# EFR32FG22C121F512GM32 register map
Vendor: Silicon Labs; Series: EFR32; File version: C
Registers are 32-bit, read-write, reset 0x0 unless marked. A register's access mark holds for its fields unless they carry their own. Offsets are from the block's base; [hi:lo] are bit positions; {n}, {i} and the like mark numbered series; 'fields as' and 'values as' point back to an identical list.

## RAC_S — RAC_S Registers
Base 0xA8020000
Same registers: RAC_NS 0xB8020000
0x00 IPVERSION ro reset 0x1
0x04 EN
  [0] EN — Enable peripheral clock to this module
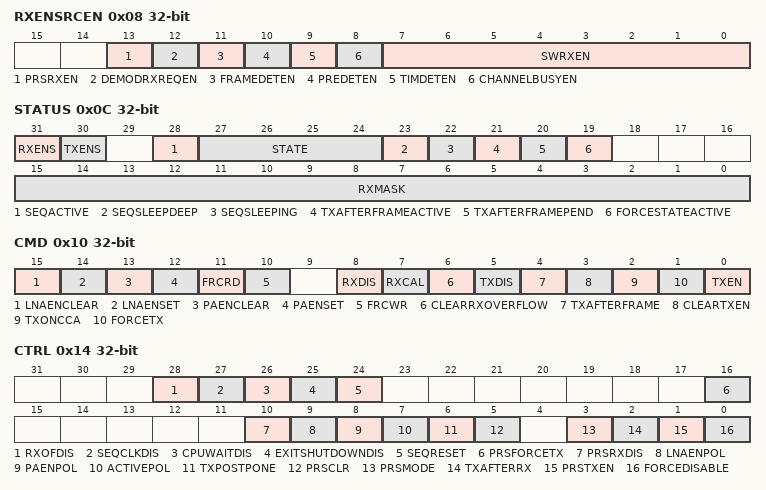
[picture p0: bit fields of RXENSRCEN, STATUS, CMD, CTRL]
0x08 RXENSRCEN
  [13] PRSRXEN — PRS RX Enable
  [12] DEMODRXREQEN — DEMOD RX Request Enable
  [11] FRAMEDETEN — Frame Detected Enable
  [10] PREDETEN — Preamble Detected Enable
  [9] TIMDETEN — Timing Detected Enable
  [8] CHANNELBUSYEN — Channel Busy Enable
  [7:0] SWRXEN — SW RX Enable
0x0C STATUS ro
  [31] RXENS — RXEN Status
    0=RXEN is not set; 1=RXEN is set
  [30] TXENS — TXEN Status
    0=TXEN is not set; 1=TXEN is set
  [28] SEQACTIVE
  [27:24] STATE — Radio State
    0=OFF (Radio is off); 1=RXWARM (Radio is enabling receiver); 2=RXSEARCH (Radio is listening for incoming frames); 3=RXFRAME (Radio is receiving a frame); 4=RXPD (Radio is powering down receiver and going to OFF state); 5=RX2RX (Radio remains in receive mode after frame reception is completed); 6=RXOVERFLOW (Received data was lost due to full receive buffer); 7=RX2TX (Radio is disabling receiver and enabling transmitter); 8=TXWARM (Radio is enabling transmitter); 9=TX (Radio is transmitting data); 10=TXPD (Radio is powering down transmitter and going to OFF state); 11=TX2RX (Radio is disabling transmitter and enabling reception); 12=TX2TX (Radio is preparing for a transmission after the previous transmission was ended); 13=SHUTDOWN (Radio is powering down receiver and going to OFF state); 14=POR (Radio power-on-reset state)
  [23] SEQSLEEPDEEP — SEQ in deep sleep
  [22] SEQSLEEPING — SEQ in sleeping
  [21] TXAFTERFRAMEACTIVE
    0=The currently ongoing TX was not initiated by a TXAFTERFRAME command; 1=The currently ongoing TX was initiated by a TXAFTERFRAME command
  [20] TXAFTERFRAMEPEND — TX After Frame Pending
    0=A transmit after frame operation is currently not pending; 1=A transmit after frame operation is currently pending
  [19] FORCESTATEACTIVE — FSM state force active
    0=No special state transition is currently in progress; 1=A forced state transition is currently in progress
  [15:0] RXMASK — Receive Enable Mask
0x10 CMD wo
  [15] LNAENCLEAR
  [14] LNAENSET
  [13] PAENCLEAR
  [12] PAENSET
  [11] FRCRD — FRC read cmd
  [10] FRCWR — FRC write cmd
  [8] RXDIS — RX Disable
  [7] RXCAL — Start an RX Calibration
  [6] CLEARRXOVERFLOW
  [5] TXDIS — TX Disable
  [4] TXAFTERFRAME
  [3] CLEARTXEN — Clear TX Enable
  [2] TXONCCA — Transmit On CCA
  [1] FORCETX — Force TX Command
  [0] TXEN — Transmitter Enable
0x14 CTRL
  [28] RXOFDIS — Switch to RXOVERFLOW Disable
  [27] SEQCLKDIS — SEQ Clk Disable
  [26] CPUWAITDIS — SEQ CPU Wait Disable
  [25] EXITSHUTDOWNDIS — Exit SHUTDOWN state Disable
  [24] SEQRESET wo
  [16] PRSFORCETX — PRS Force RX
    0=PRS will not force TX; 1=The channel selected by PRSFORCETXSEL will generate a force TX pulse
  [10] PRSRXDIS — PRS RX Disable
    0=PRS will not disable RX; 1=The channel selected by PRSRXDISSEL will generate a disable RX pulse
  [9] LNAENPOL — LNAEN signal polarity
    0=Active low; 1=Active high
  [8] PAENPOL — PAEN signal polarity
    0=Active low; 1=Active high
  [7] ACTIVEPOL — ACTIVE signal polarity
    0=Active low; 1=Active high
  [6] TXPOSTPONE
    0=In the TX state transmit data is output; 1=In the TX state an unmodulated carrier is output until this bit is cleared
  [5] PRSCLR — PRS RXEN Clear
    0=RXSEARCH (The PRS RXEN signal is cleared when the RSM state enters RXSEARCH); 1=PRSCH (The Selected PRS channel in PRSCLRSEL is used as a disable pulse)
  [3] PRSMODE — PRS RXEN Mode
    0=DIRECT (The PRS signal is used directly); 1=PULSE (The PRS signal is used as an RX enable pulse)
  [2] TXAFTERRX
    0=TX will not be started automatically; 1=A transition to TX is automatically started when a received frame is accepted by the FRC
  [1] PRSTXEN — PRS TX Enable
  [0] FORCEDISABLE — Force Radio Disable
0x18 FORCESTATE
  [3:0] FORCESTATE — Force RAC state transition
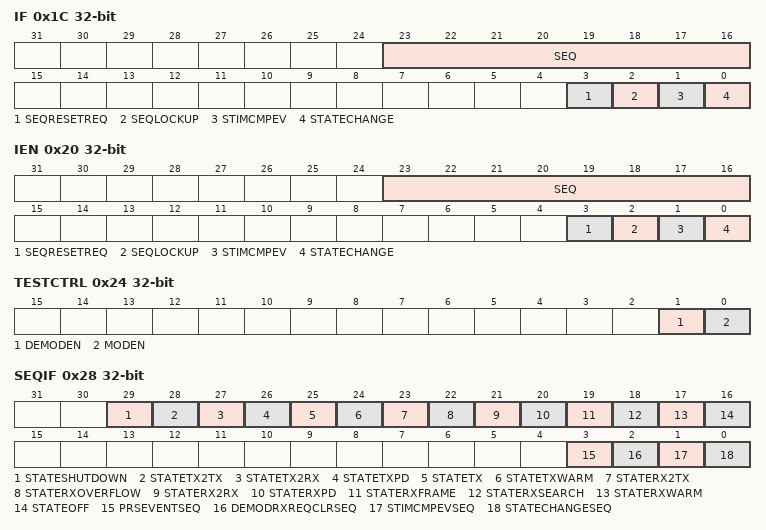
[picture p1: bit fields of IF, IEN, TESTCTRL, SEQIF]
0x1C IF
  [23:16] SEQ — Sequencer Interrupt Flags
  [3] SEQRESETREQ — SEQ reset request
  [2] SEQLOCKUP — SEQ locked up
  [1] STIMCMPEV — STIMER Compare Event
  [0] STATECHANGE — Radio State Change
0x20 IEN
  [23:16] SEQ — Sequencer Flags Interrupt Enable
  [3] SEQRESETREQ — SEQ reset request Interrupt Enable
  [2] SEQLOCKUP — SEQ locked up Interrupt Enable
  [1] STIMCMPEV — STIMER Compare Event Interrupt Enable
  [0] STATECHANGE — Radio State Change Interrupt Enable
0x24 TESTCTRL
  [1] DEMODEN — Demodulator enable
  [0] MODEN — Modulator enable
0x28 SEQIF
  [29] STATESHUTDOWN — entering STATE_SHUTDOWN
  [28] STATETX2TX — entering STATE_TX2TX
  [27] STATETX2RX — entering STATE_TX2RX
  [26] STATETXPD — entering STATE_TXPD
  [25] STATETX — entering STATE_TX
  [24] STATETXWARM — entering STATE_TXWARM
  [23] STATERX2TX — entering STATE_RX2TX
  [22] STATERXOVERFLOW — entering STATE_RXOVERFLOW
  [21] STATERX2RX — entering STATE_RX2RX
  [20] STATERXPD — entering STATE_RXPD
  [19] STATERXFRAME — entering STATE_RXFRAME
  [18] STATERXSEARCH — entering STATE_RXSEARCH
  [17] STATERXWARM — entering STATE_RXWARM
  [16] STATEOFF — entering STATE_OFF
  [3] PRSEVENTSEQ — SEQ PRS Event
  [2] DEMODRXREQCLRSEQ — Demod RX request clear
  [1] STIMCMPEVSEQ — STIMER Compare Event
  [0] STATECHANGESEQ — Radio State Change
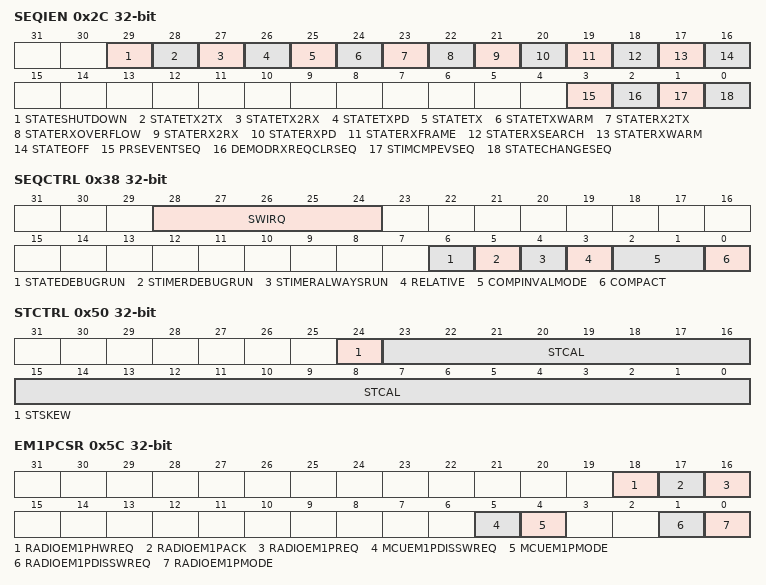
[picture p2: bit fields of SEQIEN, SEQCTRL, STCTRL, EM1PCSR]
0x2C SEQIEN
  [29] STATESHUTDOWN — STATE_SHUTDOWN Interrupt Enable
  [28] STATETX2TX — STATE_TX2TX Interrupt Enable
  [27] STATETX2RX — STATE_TX2RX Interrupt Enable
  [26] STATETXPD — STATE_TXPD Interrupt Enable
  [25] STATETX — STATE_TX Interrupt Enable
  [24] STATETXWARM — STATE_TXWARM Interrupt Enable
  [23] STATERX2TX — STATE_RX2TX Interrupt Enable
  [22] STATERXOVERFLOW — STATE_RXOVERFLOW Interrupt Enable
  [21] STATERX2RX — STATE_RX2RX Interrupt Enable
  [20] STATERXPD — STATE_RXPD Interrupt Enable
  [19] STATERXFRAME — STATE_RXFRAME Interrupt Enable
  [18] STATERXSEARCH — STATE_RXSEARC Interrupt Enable
  [17] STATERXWARM — STATE_RXWARM Interrupt Enable
  [16] STATEOFF — STATE_OFF Interrupt Enable
  [3] PRSEVENTSEQ — PRS SEQ EVENT Interrupt Enable
  [2] DEMODRXREQCLRSEQ — Demod RX req clr Interrupt Enable
  [1] STIMCMPEVSEQ — STIMER Compare Event Interrupt Enable
  [0] STATECHANGESEQ — Radio State Change Interrupt Enable
0x30 STIMER ro
  [15:0] STIMER
0x34 STIMERCOMP
  [15:0] STIMERCOMP — STIMER Compare Register
0x38 SEQCTRL
  [28:24] SWIRQ — SW spare IRQ
  [6] STATEDEBUGRUN — FSM state Debug Run
    0=FSM keeps unchanged when the Sequencer is halted; 1=FSM keeps going when the Sequencer is halted
  [5] STIMERDEBUGRUN
    0=STIMER is not running when the Sequencer is halted; 1=STIMER is running when the Sequencer is halted
  [4] STIMERALWAYSRUN
  [3] RELATIVE — STIMER Compare value relative
    0=Absolute (The compare value set for stimer is an absolute value.); 1=Relative (The compare value set for stimer is a relative value. It takes the amount of time you set to make compare event happens.)
  [2:1] COMPINVALMODE — STIMER Comp Invalid Mode
    0=NEVER (STIMERCOMP is always valid); 1=STATECHANGE (STIMERCOMP is invalidated when the RSM changes state); 2=COMPEVENT (STIMERCOMP is invalidated when an STIMER compare event occurs); 3=STATECOMP (STIMERCOMP is invalidated both when the RSM changes state and when a compare event occurs)
  [0] COMPACT — STIMER Compare Action
    0=WRAP (STIMER wraps when reaching STIMERCOMP); 1=CONTINUE (STIMER continues when reaching STIMERCOMP)
0x3C PRESC reset 0x7
  [6:0] STIMER — STIMER Prescaler
{0x40+4i} SR{i} (i=0..3)
  [31:0] SR{i} — Sequencer Storage Register {i}
0x50 STCTRL
  [24] STSKEW — Systick timer skew
  [23:0] STCAL — Systick timer freq cal
0x54 FRCTXWORD
  [7:0] WDATA — FRC write data
0x58 FRCRXWORD ro
  [7:0] RDATA — FRC read data
0x5C EM1PCSR
  [18] RADIOEM1PHWREQ ro
  [17] RADIOEM1PACK ro
  [16] RADIOEM1PREQ ro
  [5] MCUEM1PDISSWREQ
  [4] MCUEM1PMODE
    0=HWCTRL (Hardware Controls EM1P Request Signal.); 1=SWCTRL (Software Controls EM1P Request Signal)
  [1] RADIOEM1PDISSWREQ
  [0] RADIOEM1PMODE
    0=HWCTRL (Hardware Controls EM1P Request Signal); 1=SWCTRL (Software Controls EM1P Request Signal)
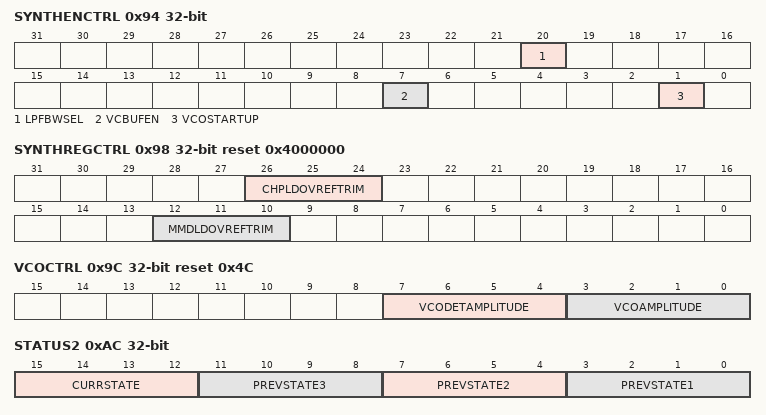
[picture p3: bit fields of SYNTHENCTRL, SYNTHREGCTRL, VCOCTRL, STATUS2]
0x94 SYNTHENCTRL
  [20] LPFBWSEL — LPF bandwidth register selection
    0=LPFBWRX (Select LPFBWRX); 1=LPFBWTX (Select LPFBWTX)
  [7] VCBUFEN — SYLPFVCBUFEN
    0=Disabled; 1=Enabled
  [1] VCOSTARTUP — SYVCOFASTSTARTUP
    0=fast_start_up_0; 1=fast_start_up_1
0x98 SYNTHREGCTRL reset 0x4000000
  [26:24] CHPLDOVREFTRIM — SYTRIMCHPREGVREF
    0=vref0p6000; 1=vref0p6125; 2=vref0p6250; 3=vref0p6375; 4=vref0p6500; 5=vref0p6625; 6=vref0p6750; 7=vref0p6875
  [12:10] MMDLDOVREFTRIM — SYTRIMMMDREGVREF
    values as CHPLDOVREFTRIM
0x9C VCOCTRL reset 0x4C
  [7:4] VCODETAMPLITUDE — SYVCOAMPLPKD
  [3:0] VCOAMPLITUDE — SYVCOAMPLOPEN
0xA4 SYNTHCTRL
  [10] MMDPOWERBALANCEDISABLE — SYMMDPOWERBALANCEENB
    0=EnablePowerbleed; 1=DisablePowerBleed
0xAC STATUS2 ro
  [all] fields
    values as STATUS.STATE
  [15:12] CURRSTATE — Current Radio State
  [11:8] PREVSTATE3 — Previous Radio State 3
  [7:4] PREVSTATE2 — Previous Radio State 2
  [3:0] PREVSTATE1 — Previous Radio State
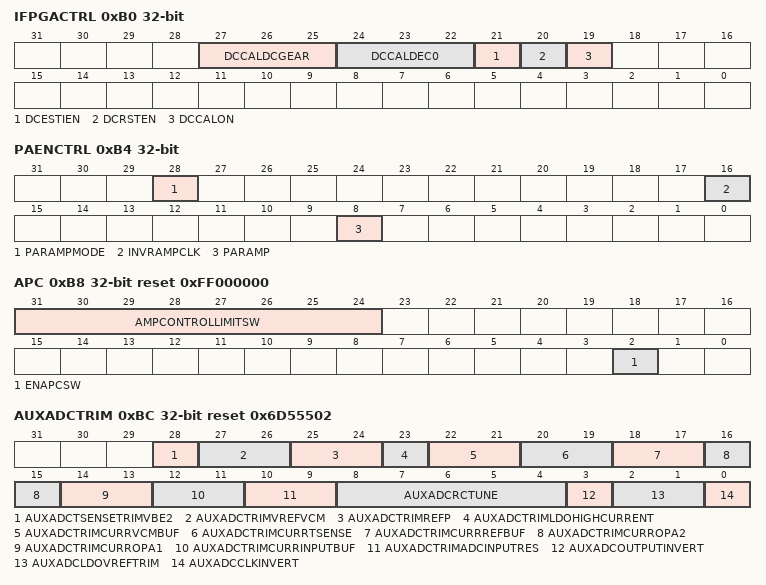
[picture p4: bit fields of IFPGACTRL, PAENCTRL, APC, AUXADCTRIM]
0xB0 IFPGACTRL
  [27:25] DCCALDCGEAR — DC COMP GEAR Value for DCCAL
  [24:22] DCCALDEC0 — DEC0 Value for DCCAL
    0=DF3 (Decimation Factor 0 = 3. Cutoff 0.050 * f<subscript>HFXO</subscript>.); 1=DF4WIDE (Decimation Factor 0 = 4. Cutoff 0.069 * f<subscript>HFXO</subscript>.); 2=DF4NARROW (Decimation Factor 0 = 4. Cutoff 0.037 * f<subscript>HFXO</subscript>.); 3=DF8WIDE (Decimation Factor 0 = 8. Cutoff 0.012 * f<subscript>HFXO</subscript>.); 4=DF8NARROW (Decimation Factor 0 = 8. Cutoff 0.005 * f<subscript>HFXO</subscript>.)
  [21] DCESTIEN — DCESTIEN Override for RAC
    0=DISABLE (DCESTI Disabled in MODEM); 1=ENABLE (DCESTI Enabled in MODEM)
  [20] DCRSTEN — DC Compensation Filter Reset Enable
    0=DISABLE (DC Comp out of Reset); 1=ENABLE (DC Comp in Reset)
  [19] DCCALON — Enable/Disable DCCAL in DEMOD
    0=DISABLE (DC ESTI DISABLED); 1=ENABLE (DC ESTI ENABLED)
0xB4 PAENCTRL
  [28] PARAMPMODE
    0=LINEAR (PA ramps in normal linear mode, ramp offset doesn't apply); 1=OFFSET (PA ramps with an pre-determined offset that is different between different PAs)
  [16] INVRAMPCLK — Invert PA ramping clock
  [8] PARAMP — PA output level ramping
0xB8 APC reset 0xFF000000
  [31:24] AMPCONTROLLIMITSW — software amp_control top limit
  [2] ENAPCSW — software control bit for apc
    0=DISABLE; 1=ENABLE
0xBC AUXADCTRIM reset 0x6D55502
  [28] AUXADCTSENSETRIMVBE2
    0=VBE_16uA; 1=VBE_32uA
  [27:26] AUXADCTRIMVREFVCM
    0=Trim0p6; 1=Trim0p65; 2=Trim0p7; 3=Trim0p75
  [25:24] AUXADCTRIMREFP
    0=REF1p05; 1=REF1p16; 2=REF1p2; 3=REF1p25
  [23] AUXADCTRIMLDOHIGHCURRENT
    0=LowCurrentMode; 1=HighCurrentMode
  [22:21] AUXADCTRIMCURRVCMBUF
    0=Typ_minus_40pct; 1=Typ_minus_20pct; 2=Typ; 3=Typ_plus_20pct
  [20:19] AUXADCTRIMCURRTSENSE
    values as AUXADCTRIMCURRVCMBUF
  [18:17] AUXADCTRIMCURRREFBUF
    values as AUXADCTRIMCURRVCMBUF
  [16:15] AUXADCTRIMCURROPA2
    values as AUXADCTRIMCURRVCMBUF
  [14:13] AUXADCTRIMCURROPA1
    values as AUXADCTRIMCURRVCMBUF
  [12:11] AUXADCTRIMCURRINPUTBUF
    values as AUXADCTRIMCURRVCMBUF
  [10:9] AUXADCTRIMADCINPUTRES
    0=RES200k; 1=RES250k; 2=RES300k; 3=RES350k
  [8:4] AUXADCRCTUNE
  [3] AUXADCOUTPUTINVERT
    0=Disabled; 1=Enabled
  [2:1] AUXADCLDOVREFTRIM
    0=TRIM1p27; 1=TRIM1p3; 2=TRIM1p35; 3=TRIM1p4
  [0] AUXADCCLKINVERT
    0=Disable_Invert; 1=Enable_Invert
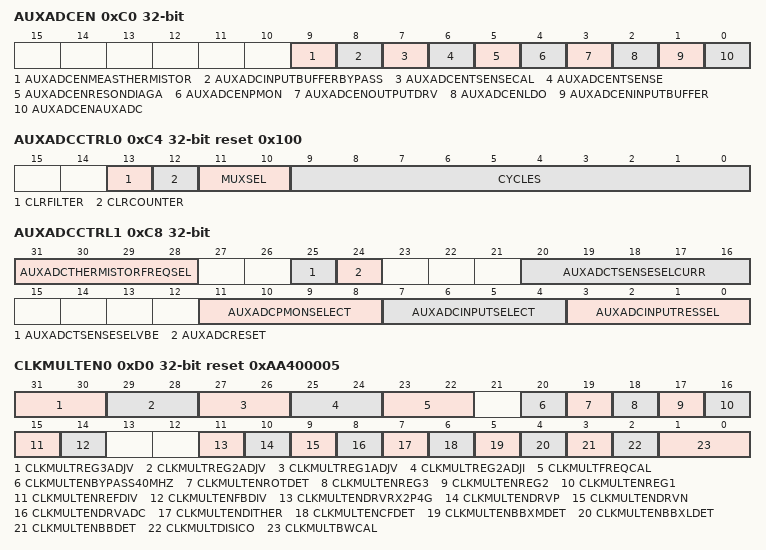
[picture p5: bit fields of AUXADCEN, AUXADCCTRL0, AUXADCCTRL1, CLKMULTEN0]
0xC0 AUXADCEN
  [9] AUXADCENMEASTHERMISTOR
    0=Disabled; 1=Enabled
  [8] AUXADCINPUTBUFFERBYPASS
    0=Not_Bypassed; 1=Bypassed
  [7] AUXADCENTSENSECAL
    0=Disabled; 1=Enabled
  [6] AUXADCENTSENSE
    0=Disabled; 1=Enabled
  [5] AUXADCENRESONDIAGA
    0=Disabled; 1=Enabled
  [4] AUXADCENPMON
    0=Disabled; 1=Enabled
  [3] AUXADCENOUTPUTDRV
    0=Disabled; 1=Enabled
  [2] AUXADCENLDO
    0=Disabled; 1=Enabled
  [1] AUXADCENINPUTBUFFER
    0=Disabled; 1=Enabled
  [0] AUXADCENAUXADC
    0=Disabled; 1=Enabled
0xC4 AUXADCCTRL0 reset 0x100
  [13] CLRFILTER — Clear accumulators
  [12] CLRCOUNTER — Clear counter
  [11:10] MUXSEL — Select accumulator
  [9:0] CYCLES — Cycle number to run
0xC8 AUXADCCTRL1
  [31:28] AUXADCTHERMISTORFREQSEL
    0=DIV1; 1=DIV2; 2=DIV4; 3=DIV8; 4=DIV16; 5=DIV32; 6=DIV64; 7=DIV128; 8=DIV256; 9=DIV512; 10=DIV1024
  [25] AUXADCTSENSESELVBE
    0=VBE1; 1=VBE2
  [24] AUXADCRESET
    0=Reset_Enabled; 1=Reset_Disabled
  [20:16] AUXADCTSENSESELCURR
  [11:8] AUXADCPMONSELECT
  [7:4] AUXADCINPUTSELECT
    {v}=SEL{v} (v=0..9)
  [3:0] AUXADCINPUTRESSEL
    0=RES640kOhm; 1=RES320kOhm; 2=RES160kOhm; 3=RES80kOhm; 4=RES40kOhm; 5=RES20kOhm; 6=RES10kOhm; 7=RES5kOhm; 8=RES2p5kOhm; 9=RES1p25kOhm; 10=RES0p6kOhm; 11=RES_switch
0xCC AUXADCOUT ro
  [27:0] AUXADCOUT — AUXADC output
0xD0 CLKMULTEN0 reset 0xAA400005
  [31:30] CLKMULTREG3ADJV
    0=v1p03; 1=v1p06; 2=v1p07; 3=v1p09
  [29:28] CLKMULTREG2ADJV
    0=v1p03; 1=v1p09; 2=v1p10; 3=v1p16
  [27:26] CLKMULTREG1ADJV
    0=v1p28; 1=v1p32; 2=v1p33; 3=v1p38
  [25:24] CLKMULTREG2ADJI
    0=I_80uA; 1=I_100uA; 2=I_120uA; 3=I_140uA
  [23:22] CLKMULTFREQCAL
    0=pedes_14uA; 1=pedes_22uA; 2=pedes_30uA; 3=pedes_38uA
  [20] CLKMULTENBYPASS40MHZ
    0=disable; 1=enable
  [19] CLKMULTENROTDET
    0=disable; 1=enable
  [18] CLKMULTENREG3
    0=disable; 1=enable
  [17] CLKMULTENREG2
    0=disable; 1=enable
  [16] CLKMULTENREG1
    0=disable; 1=enable
  [15] CLKMULTENREFDIV
    0=disable; 1=enable
  [14] CLKMULTENFBDIV
    0=disable; 1=enable
  [11] CLKMULTENDRVRX2P4G
    0=disable; 1=enable
  [10] CLKMULTENDRVP
    0=disable; 1=enable
  [9] CLKMULTENDRVN
    0=disable; 1=enable
  [8] CLKMULTENDRVADC
    0=disable; 1=enable
  [7] CLKMULTENDITHER
    0=disable; 1=enable
  [6] CLKMULTENCFDET
    0=disable; 1=enable
  [5] CLKMULTENBBXMDET
    0=disable; 1=enable
  [4] CLKMULTENBBXLDET
    0=disable; 1=enable
  [3] CLKMULTENBBDET
    0=disable; 1=enable
  [2] CLKMULTDISICO
    0=enable; 1=disable
  [1:0] CLKMULTBWCAL
    {v}=bw_{v+1}lsb (v=0..3)
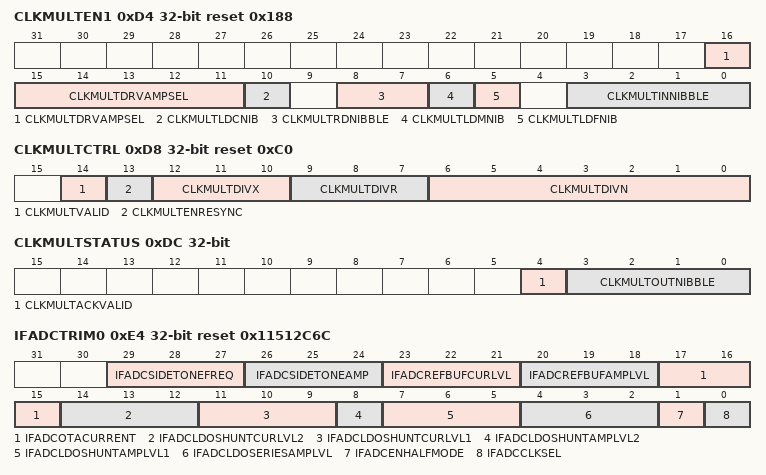
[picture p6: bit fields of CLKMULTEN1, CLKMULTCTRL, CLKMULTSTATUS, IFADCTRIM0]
0xD4 CLKMULTEN1 reset 0x188
  [16:11] CLKMULTDRVAMPSEL
    0=off; 1=slide_x1; 3=slide_x2; 7=slide_x3; 15=slide_x4; 31=slide_x5; 63=slide_x6
  [10] CLKMULTLDCNIB
    0=disable; 1=enable
  [8:7] CLKMULTRDNIBBLE
    0=quarter_nibble; 1=fine_nibble; 2=moderate_nibble; 3=coarse_nibble
  [6] CLKMULTLDMNIB
    0=disable; 1=enable
  [5] CLKMULTLDFNIB
    0=disable; 1=enable
  [3:0] CLKMULTINNIBBLE
0xD8 CLKMULTCTRL reset 0xC0
  [14] CLKMULTVALID
    0=invalid; 1=valid
  [13] CLKMULTENRESYNC
    0=disable_sync; 1=enable_sync
  [12:10] CLKMULTDIVX
    0=div_1; 1=div_2; 2=div_4; 3=div_6; 4=div_8; 5=div10; 6=div12; 7=div14
  [9:7] CLKMULTDIVR
  [6:0] CLKMULTDIVN
0xDC CLKMULTSTATUS ro
  [4] CLKMULTACKVALID
    0=invalid; 1=valid
  [3:0] CLKMULTOUTNIBBLE
0xE4 IFADCTRIM0 reset 0x11512C6C
  [29:27] IFADCSIDETONEFREQ
    0=na0; 1=div_128; 2=div_64; 3=div_32; 4=div_16; 5=div_8; 6=div_4; 7=na7
  [26:24] IFADCSIDETONEAMP
    0=diff_5p68mV; 1=diff_29p1mV; 2=diff_9p73mV; 3=diff_76p9mV; 4=diff_9p68_mV; 5=diff_51_mV; 6=diff_17p2_mV; 7=disable
  [23:21] IFADCREFBUFCURLVL
    0=i4u; 1=i4p5u; 2=i5u; 3=i5p5u; 4=i5u2; 5=i5p5u2; 6=i6u; 7=i6p5u
  [20:18] IFADCREFBUFAMPLVL
    0=v0p88; 1=v0p91; 2=v0p94; 3=v0p97; 4=v1p00; 5=v1p03; 6=v1p06; 7=v1p09
  [17:15] IFADCOTACURRENT
    0=i3u; 1=i3p5u; 2=i4u; 3=i4p5u; 4=i4u2; 5=i4p5u2; 6=i5u; 7=i5p5u
  [14:12] IFADCLDOSHUNTCURLVL2
    values as IFADCREFBUFCURLVL
  [11:9] IFADCLDOSHUNTCURLVL1
    0=i55u; 1=i65u; 2=i70u; 3=i85u; 4=i85u2; 5=i95u; 6=i100u; 7=i110u
  [8] IFADCLDOSHUNTAMPLVL2
    0=disable; 1=enable
  [7:5] IFADCLDOSHUNTAMPLVL1
    0=v1p125; 1=v1p150; 2=v1p175; 3=v1p200; 4=v1p225; 5=v1p250; 6=v1p275; 7=v1p300
  [4:2] IFADCLDOSERIESAMPLVL
    0=v1p225; 1=v1p250; 2=v1p275; 3=v1p300; 4=v1p325; 5=v1p350; 6=v1p375; 7=v1p400
  [1] IFADCENHALFMODE
    0=full_speed_mode; 1=half_speed_mode
  [0] IFADCCLKSEL
    0=clk_2p4g; 1=clk_subg
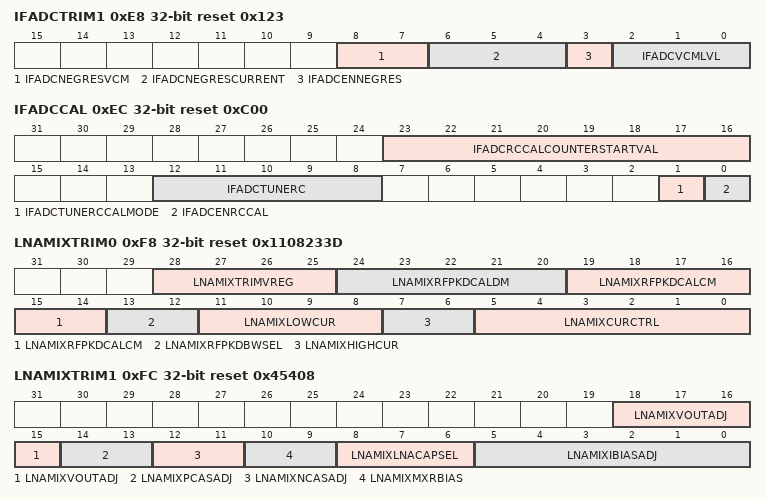
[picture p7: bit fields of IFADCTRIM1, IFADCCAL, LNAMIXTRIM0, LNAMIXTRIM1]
0xE8 IFADCTRIM1 reset 0x123
  [8:7] IFADCNEGRESVCM
    0=r210k_x_1uA; 1=r210k_x_1uA2; 2=r100k_x_2uA; 3=r50k_x_3uA
  [6:4] IFADCNEGRESCURRENT
    0=i1p0u; 1=i1p5u; 2=i2p0u; 3=i2p5u; 4=i2p0u2; 5=i2p5u2; 6=i3p0u; 7=i3p5u
  [3] IFADCENNEGRES
    0=disable; 1=enable
  [2:0] IFADCVCMLVL
    0=vcm_475mV; 1=vcm_500mV; 2=vcm_525mV; 3=vcm_550mV; 4=vcm_575mV; 5=vcm_600mV; 6=vcm_625mV; 7=cm_650mV
0xEC IFADCCAL reset 0xC00
  [23:16] IFADCRCCALCOUNTERSTARTVAL
  [12:8] IFADCTUNERC
  [1] IFADCTUNERCCALMODE
    0=SYmode; 1=ADCmode
  [0] IFADCENRCCAL
    0=rccal_disable; 1=rccal_enable
0xF0 IFADCSTATUS ro
  [0] IFADCRCCALOUT
    0=lo; 1=hi
0xF8 LNAMIXTRIM0 reset 0x1108233D
  [28:25] LNAMIXTRIMVREG
  [24:20] LNAMIXRFPKDCALDM
  [19:14] LNAMIXRFPKDCALCM
  [13:12] LNAMIXRFPKDBWSEL
  [11:8] LNAMIXLOWCUR
  [7:6] LNAMIXHIGHCUR
    0=current_470uA; 1=current_530uA; 3=current_590uA
  [5:0] LNAMIXCURCTRL
0xFC LNAMIXTRIM1 reset 0x45408
  [18:15] LNAMIXVOUTADJ
  [14:13] LNAMIXPCASADJ
    0=pcas_250m; 2=pcas_300m; 3=pcas_350m
  [12:11] LNAMIXNCASADJ
    0=ncas_1V; 2=ncas_950m; 3=ncas_900m
  [10:9] LNAMIXMXRBIAS
    0=bias_1V; 2=bias_900m; 3=bias_800m
  [8:6] LNAMIXLNACAPSEL
  [5:0] LNAMIXIBIASADJ
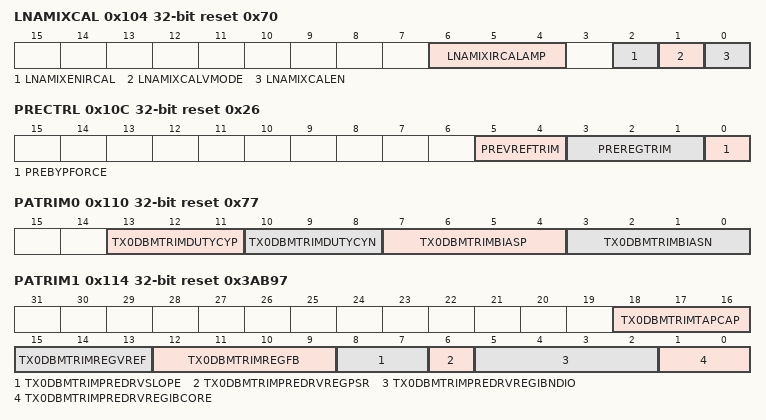
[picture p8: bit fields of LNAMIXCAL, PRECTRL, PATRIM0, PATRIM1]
0x104 LNAMIXCAL reset 0x70
  [6:4] LNAMIXIRCALAMP
  [2] LNAMIXENIRCAL
    0=disable; 1=enable
  [1] LNAMIXCALVMODE
    0=current_mode; 1=voltage_mode
  [0] LNAMIXCALEN
    0=cal_disable; 1=cal_enable
0x108 LNAMIXEN
  [0] LNAMIXENLDO
    0=disable; 1=enable
0x10C PRECTRL reset 0x26
  [5:4] PREVREFTRIM
    0=v0p675; 1=v0p688; 2=v0p700; 3=v0p713
  [3:1] PREREGTRIM
    0=v1p61; 1=v1p68; 2=v1p74; 3=v1p80; 4=v1p86; 5=v1p91; 6=v1p96; 7=v2p00
  [0] PREBYPFORCE
    0=not_forced; 1=forced
0x110 PATRIM0 reset 0x77
  [13:11] TX0DBMTRIMDUTYCYP
    {v}=dn_{v}pct (v=0..6); 7=na
  [10:8] TX0DBMTRIMDUTYCYN
    {v}=up_{v}pct (v=0..6); 7=na
  [7:4] TX0DBMTRIMBIASP
    0=v_378m; 1=v_392m; 2=v_405m; 3=v_418p5m; 4=v_431m; 5=v_444m; 6=v_457m; 7=v_470m; 8=v_483m; 9=v_496m; 10=v_509m; 11=v_522m; 12=v_535m; 13=v_548m; 14=v_561m; 15=v_574m
  [3:0] TX0DBMTRIMBIASN
    values as TX0DBMTRIMBIASP
0x114 PATRIM1 reset 0x3AB97
  [18:16] TX0DBMTRIMTAPCAP
    0=cap_0F; 1=cap_0p35pF; 2=cap_0p7pF; 3=cap_1p05pF; 4=cap_1p4pF; 5=cap_1p75pF; 6=cap_2p1pF; 7=cap_2p45pF
  [15:13] TX0DBMTRIMREGVREF
    0=v_900m; 1=v_912p5m; 2=v_925m; 3=v_937p5m; 4=v_950m; 5=v_962p5m; 6=v_975m; 7=v_987p5m
  [12:9] TX0DBMTRIMREGFB
    0=vo_vi_0p475; 1=vo_vi_0p500; 2=vo_vi_0p525; 3=vo_vi_0p550; 4=vo_vi_0p575; 5=vo_vi_0p600; 6=vo_vi_0p625; 7=vo_vi_0p650; 8=vo_vi_0p675; 9=vo_vi_0p700; 10=vo_vi_0p725; 11=vo_vi_0p750; 12=vo_vi_0p775; 13=vo_vi_0p800; 14=vo_vi_0p825; 15=vo_vi_0p850
  [8:7] TX0DBMTRIMPREDRVSLOPE
    0=slope_0; 1=slope_1; 2=slope_2; 3=slope_max
  [6] TX0DBMTRIMPREDRVREGPSR
    0=disable; 1=enable
  [5:2] TX0DBMTRIMPREDRVREGIBNDIO
    0=vreg_1p127; 1=vreg_1p171; 2=vreg_1p209; 3=vreg_1p244; 4=vreg_1p275; 5=vreg_1p305; 6=vreg_1p335; 7=vreg_1p363; 8=vreg_1p388; 9=vreg_1p414; 10=vreg_1p439; 11=vreg_1p464; 12=vreg_1p486; 13=vreg_1p506; 14=vreg_1p525; 15=vreg_1p545
  [1:0] TX0DBMTRIMPREDRVREGIBCORE
    {v}=i_{v+4}u (v=0..3)
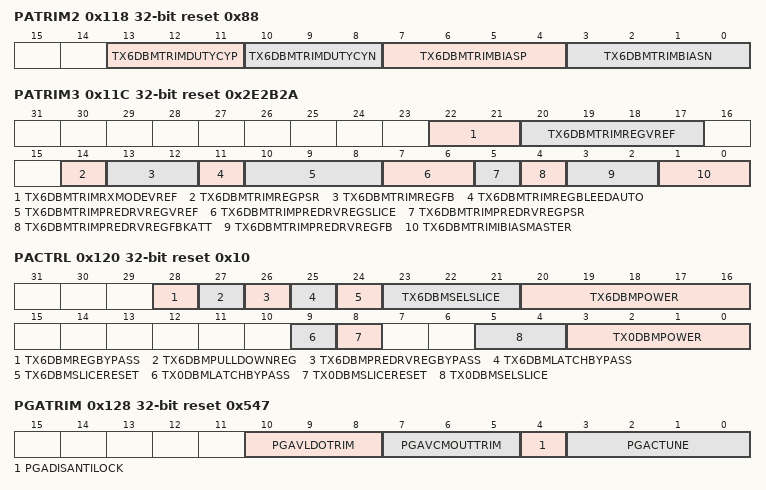
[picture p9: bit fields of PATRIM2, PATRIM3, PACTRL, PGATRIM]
0x118 PATRIM2 reset 0x88
  [13:11] TX6DBMTRIMDUTYCYP
    {v}=dn_{v}pct (v=0..6); 7=na
  [10:8] TX6DBMTRIMDUTYCYN
    {v}=up_{v}pct (v=0..6); 7=na
  [7:4] TX6DBMTRIMBIASP
    0=vpbias_dn104mV; 1=vpbias_dn91mV; 2=vpbias_dn78mV; 3=vpbias_dn65mV; 4=vpbias_dn52mV; 5=vpbias_dn39mV; 6=vpbias_dn26mV; 7=vpbias_dn13mV; 8=vpbias_default_949mV; 9=vpbias_up13mV; 10=vpbias_up26mV; 11=vpbias_up39mV; 12=vpbias_up52mV; 13=vpbias_up65mV; 14=vpbias_up78mV; 15=vpbias_up91mV
  [3:0] TX6DBMTRIMBIASN
    0=vnbias_dn104mV; 1=vnbias_dn91mV; 2=vnbias_dn78mV; 3=vnbias_dn65mV; 4=vnbias_dn52mV; 5=vnbias_dn39mV; 6=vnbias_dn26mV; 7=vnbias_dn13mV; 8=vnbias_default_613mV; 9=vnbias_up13mV; 10=vnbias_up26mV; 11=vnbias_up39mV; 12=vnbias_up52mV; 13=vnbias_up65mV; 14=vnbias_up78mV; 15=vnbias_up91mV
0x11C PATRIM3 reset 0x2E2B2A
  [22:21] TX6DBMTRIMRXMODEVREF
    0=vddreg_1p05; 1=vddreg_1p14; 2=vddreg_1p20; 3=vddreg_1p23
  [20:17] TX6DBMTRIMREGVREF
    0=vref_0p6000; 1=vref_0p6125; 2=vref_0p6250; 3=vref_0p6375; 4=vref_0p6500; 5=vref_0p6625; 6=vref_0p6750; 7=vref_0p6875; 8=vref_0p7000; 9=vref_0p7125; 10=vref_0p7250; 11=vref_0p7375; 12=vref_0p7500; 13=vref_0p7625; 14=vref_0p7750; 15=vref_0p7875
  [14] TX6DBMTRIMREGPSR
    0=low_PSR; 1=high_PSR
  [13:12] TX6DBMTRIMREGFB
    0=Acl_2p0x; 1=Acl_2p1x; 2=Acl_2p3125x; 3=Acl_2p5x
  [11] TX6DBMTRIMREGBLEEDAUTO
    0=not_automatic; 1=automatic
  [10:8] TX6DBMTRIMPREDRVREGVREF
    0=vref_0p675; 1=vref_0p700; 2=vref_0p725; 3=vref_0p750; 4=vref_0p775; 5=vref_0p800; 6=vref_0p825; 7=vref_0p850
  [7:6] TX6DBMTRIMPREDRVREGSLICE
    0=iload_3mA; 1=iload_6mA; 2=iload_9mA; 3=iload_12mA
  [5] TX6DBMTRIMPREDRVREGPSR
    0=low_psr; 1=high_psr
  [4] TX6DBMTRIMPREDRVREGFBKATT
    0=reduce_BW; 1=increase_BW
  [3:2] TX6DBMTRIMPREDRVREGFB
    0=Acl_1p63; 1=Acl_1p71; 2=Acl_1p80; 3=Acl_1p92
  [1:0] TX6DBMTRIMIBIASMASTER
    0=ibias_45u; 1=ibias_47p5u; 2=ibias_50u; 3=ibias_52p5u
0x120 PACTRL reset 0x10
  [28] TX6DBMREGBYPASS
    0=not_bypass; 1=bypass
  [27] TX6DBMPULLDOWNREG
    0=not_pull_down; 1=pull_down
  [26] TX6DBMPREDRVREGBYPASS — TX6DBMREGBYPASSPDRVLDo
    0=not_bypass; 1=bypass
  [25] TX6DBMLATCHBYPASS
    0=not_bypass; 1=bypass_latch
  [24] TX6DBMSLICERESET
    0=disable_reset; 1=enable_reset
  [23:21] TX6DBMSELSLICE
    {v}=n_slice_on_{v} (v=0..4); 5=tbd_5; 6=tbd_6; 7=tbd_7
  [20:16] TX6DBMPOWER
  [9] TX0DBMLATCHBYPASS
    0=disable; 1=enable
  [8] TX0DBMSLICERESET
    0=active; 1=reset
  [5:4] TX0DBMSELSLICE
    0=on_0_slice; 1=on_1_slices; 2=on_2_slices; 3=NA
  [3:0] TX0DBMPOWER
    0=on_stripe_0; 12=on_stripe_12
0x128 PGATRIM reset 0x547
  [10:8] PGAVLDOTRIM
    0=vdda_1p15; 1=vdda_1p2; 2=vdda_1p25; 3=vdda_1p3; 4=vdda_1p35; 5=vdda_1p4; 6=vdda_1p5; 7=vdda_1p55
  [7:5] PGAVCMOUTTRIM
    0=vcm_out_0p4; 1=vcm_out_0p45; 2=vcm_out_0p5; 3=vcm_out_0p55; 4=vcm_out_0p6; 5=vcm_out_0p65; 6=vcm_out_0p7; 7=vcm_out_0p75
  [4] PGADISANTILOCK
    0=antilock_enable; 1=antilock_disable
  [3:0] PGACTUNE
    0=cfb_0p7; 7=cfb_nominal; 15=cfb_1p32
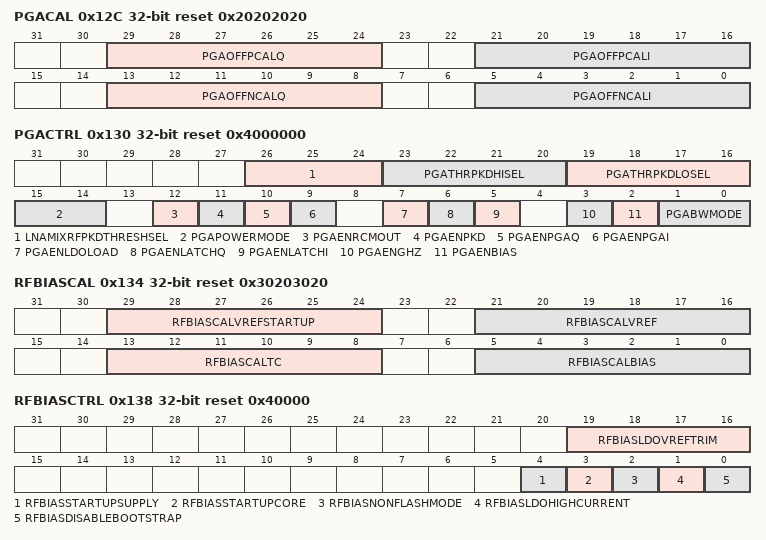
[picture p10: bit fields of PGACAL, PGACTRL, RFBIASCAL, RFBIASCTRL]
0x12C PGACAL reset 0x20202020
  [all] fields
    0=offset_m_300mv; 63=offset_p_300mv
  [29:24] PGAOFFPCALQ
  [21:16] PGAOFFPCALI
  [13:8] PGAOFFNCALQ
  [5:0] PGAOFFNCALI
0x130 PGACTRL reset 0x4000000
  [26:24] LNAMIXRFPKDTHRESHSEL
  [23:20] PGATHRPKDHISEL
    0=vref50mv; 1=vref75mv; 2=vref100mv; 3=vref125mv; 4=verf150mv; 5=vref175mv; 6=vref200mv; 7=vref225mv; 8=vref250mv; 9=vref275mv; 10=vref300mv
  [19:16] PGATHRPKDLOSEL
    0=vref50mv; 1=vref75mv; 2=vref100mv; 3=vref125mv; 4=vref150mv; 5=vref175mv; 6=vref200mv; 7=vref225mv; 8=vref250mv; 9=vref275mv; 10=vref300mv
  [15:14] PGAPOWERMODE
    0=pm_typ; 1=pm_0p9; 2=pm_1p2; 3=pm_0p8
  [12] PGAENRCMOUT
    0=rcm_out_disable; 1=rcm_out_enable
  [11] PGAENPKD
    0=pkd_disable; 1=pkd_enable
  [10] PGAENPGAQ
    0=pgaq_disable; 1=pgaq_enable
  [9] PGAENPGAI
    0=pgai_disable; 1=pgai_enable
  [7] PGAENLDOLOAD
    0=disable_ldo_load; 1=enable_ldo_load
  [6] PGAENLATCHQ
    0=pkd_latch_q_disable; 1=pkd_latch_q_enable
  [5] PGAENLATCHI
    0=pkd_latch_i_disable; 1=pkd_latch_i_enable
  [3] PGAENGHZ
    0=ghz_disable; 1=ghz_enable
  [2] PGAENBIAS
    0=bias_disable; 1=bias_enable
  [1:0] PGABWMODE
    0=bw_5MHz; 1=bw_2p5MHz; 2=bw_1p67MHz; 3=bw_1p25MHz
0x134 RFBIASCAL reset 0x30203020
  [29:24] RFBIASCALVREFSTARTUP, [21:16] RFBIASCALVREF, [13:8] RFBIASCALTC, [5:0] RFBIASCALBIAS
0x138 RFBIASCTRL reset 0x40000
  [19:16] RFBIASLDOVREFTRIM
    0=vref_v0p800; 1=vref_v0p813; 2=vref_v0p825; 3=vref_v0p837; 4=vref_v0p850; 5=vref_v0p863; 6=vref_v0p875; 7=vref_v0p887; 8=vref_v0p900; 9=vref_v0p913; 10=vref_v0p925; 11=vref_v0p938; 12=vref_v0p950; 13=vref_v0p963; 14=vref_v0p975; 15=vref_v0p988
  [4] RFBIASSTARTUPSUPPLY
    0=default; 1=forc_start
  [3] RFBIASSTARTUPCORE
    0=default; 1=force_start
  [2] RFBIASNONFLASHMODE
    0=flash_process; 1=non_flash_process
  [1] RFBIASLDOHIGHCURRENT
    0=low_current; 1=high_current
  [0] RFBIASDISABLEBOOTSTRAP
    0=enable_startup; 1=disable_startup
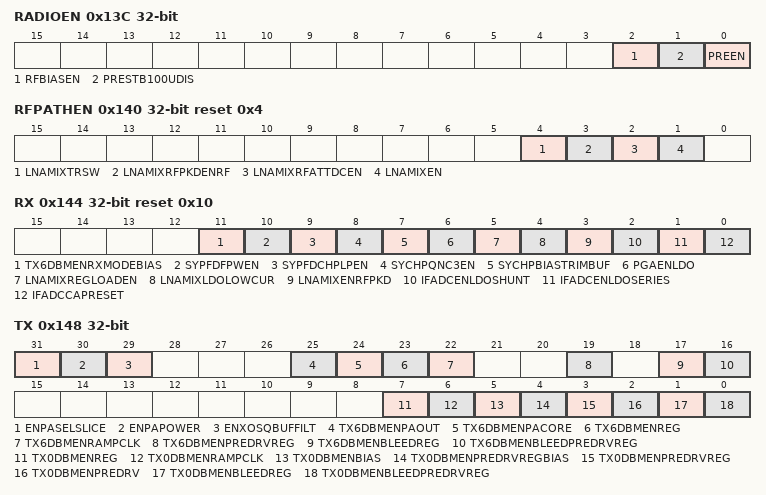
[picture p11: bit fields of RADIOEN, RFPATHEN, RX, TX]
0x13C RADIOEN
  [2] RFBIASEN
    0=disable_rfis_vtr; 1=enable_rfis_vtr
  [1] PRESTB100UDIS
    0=i100ua_enabled; 1=i100ua_disabled
  [0] PREEN
    0=powered_off; 1=powered_on
0x140 RFPATHEN reset 0x4
  [4] LNAMIXTRSW
    0=disabled; 1=enabled
  [3] LNAMIXRFPKDENRF
    0=disable; 1=enable_path
  [2] LNAMIXRFATTDCEN
    0=disable_dc; 1=enable_dc
  [1] LNAMIXEN
    0=disable; 1=enable
0x144 RX reset 0x10
  [11] TX6DBMENRXMODEBIAS
    0=Disable; 1=Enable
  [10] SYPFDFPWEN
    0=disable; 1=enable
  [9] SYPFDCHPLPEN
    0=disable; 1=enable
  [8] SYCHPQNC3EN
    0=qnc_2; 1=qnc_3
  [7] SYCHPBIASTRIMBUF
    0=i_tail_10u; 1=i_tail_20u
  [6] PGAENLDO
    0=disable_ldo; 1=enable_ldo
  [5] LNAMIXREGLOADEN
    0=disable_resistor; 1=enable_resistor
  [4] LNAMIXLDOLOWCUR
    0=regular_mode; 1=low_current_mode
  [3] LNAMIXENRFPKD
    0=disable; 1=enable
  [2] IFADCENLDOSHUNT
    0=shunt_ldo_disable; 1=shunt_ldo_enable
  [1] IFADCENLDOSERIES
    0=series_ldo_disable; 1=series_ldo_enable
  [0] IFADCCAPRESET
    0=cap_reset_disable; 1=cap_reset_enable
0x148 TX
  [31] ENPASELSLICE — Override
  [30] ENPAPOWER — Override
  [29] ENXOSQBUFFILT — Override
  [25] TX6DBMENPAOUT
    0=disable; 1=enable
  [24] TX6DBMENPACORE
    0=disable; 1=enable
  [23] TX6DBMENREG
    0=disable; 1=enable
  [22] TX6DBMENRAMPCLK
    0=disable_clock; 1=enable_clock
  [19] TX6DBMENPREDRVREG
    0=disable; 1=enable
  [17] TX6DBMENBLEEDREG
    0=disable; 1=enable
  [16] TX6DBMENBLEEDPREDRVREG
    0=disable; 1=enable
  [7] TX0DBMENREG
    0=disable; 1=enable
  [6] TX0DBMENRAMPCLK
    0=disable; 1=enable
  [5] TX0DBMENBIAS
    0=disable; 1=enable
  [4] TX0DBMENPREDRVREGBIAS
    0=disable; 1=enable
  [3] TX0DBMENPREDRVREG
    0=disable; 1=enable
  [2] TX0DBMENPREDRV
    0=disable; 1=enable
  [1] TX0DBMENBLEEDREG
    0=disable; 1=enable
  [0] TX0DBMENBLEEDPREDRVREG
    0=disable; 1=enable
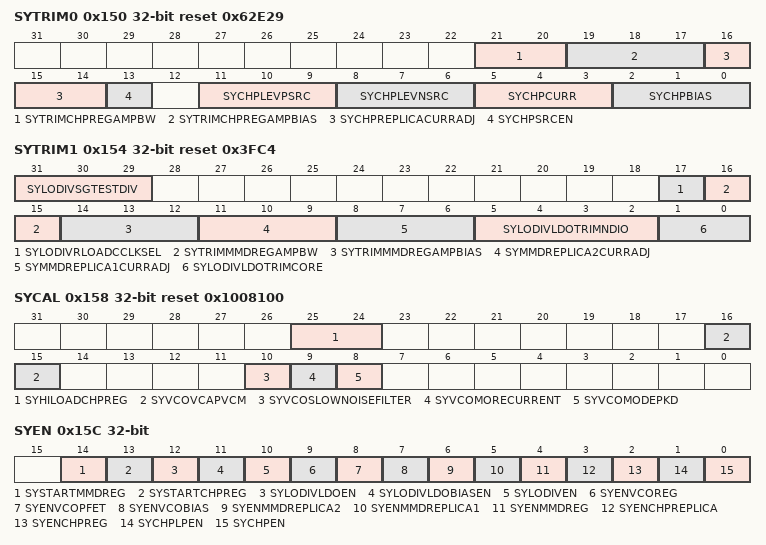
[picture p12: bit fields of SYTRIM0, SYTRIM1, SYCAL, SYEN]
0x150 SYTRIM0 reset 0x62E29
  [21:20] SYTRIMCHPREGAMPBW
    0=C_000f; 1=C_300f; 2=C_600f; 3=C_900f
  [19:17] SYTRIMCHPREGAMPBIAS
    0=bias_14uA; 1=bias_20uA; 2=bias_26uA; 3=bias_32uA; 4=bias_38uA; 5=bias_44uA; 6=bias_50uA; 7=bias_56uA
  [16:14] SYCHPREPLICACURRADJ
    0=load_8ua; 1=load_16ua; 2=load_20ua; 3=load_28ua; 4=load_24ua; 5=load_32ua; 6=load_36ua; 7=load_44ua
  [13] SYCHPSRCEN
    0=disable; 1=enable
  [11:9] SYCHPLEVPSRC
    0=vsrcp_n105m; 1=vsrcp_n90m; 2=vsrcp_n75m; 3=vsrcp_n60m; 4=vsrcp_n45m; 5=vsrcp_n30m; 6=vsrcp_n15m; 7=vsrcp_n0m
  [8:6] SYCHPLEVNSRC
  [5:3] SYCHPCURR
    0=curr_1p5uA; 1=curr_2p0uA; 2=curr_2p5uA; 3=curr_3p0uA; 4=curr_3p5uA; 5=curr_4p0uA; 6=curr_4p5uA; 7=curr_5p0uA
  [2:0] SYCHPBIAS
    0=bias_0; 1=bias_1; 3=bias_2; 7=bias_3
0x154 SYTRIM1 reset 0x3FC4
  [31:29] SYLODIVSGTESTDIV
    0=div2; 1=div3; 2=div4; 3=div6; 4=div8; 5=div12; 6=div16; 7=div12x
  [17] SYLODIVRLOADCCLKSEL
    0=adc_clk_div8; 1=adc_clk_div16
  [16:15] SYTRIMMMDREGAMPBW
    0=C_000f; 1=C_300f; 2=C_600f; 3=C_900f
  [14:12] SYTRIMMMDREGAMPBIAS
    values as SYTRIM0.SYTRIMCHPREGAMPBIAS
  [11:9] SYMMDREPLICA2CURRADJ
    0=load_32u; 1=load_64u; 2=load_96u; 3=load_128u; 4=load_160u; 5=load_192u; 6=load_224u; 7=load_256u
  [8:6] SYMMDREPLICA1CURRADJ
    0=load_8ua; 1=load_16u; 2=load_20ua; 3=load_28ua; 4=load_24ua; 5=load_32ua; 6=load_36ua; 7=load_44ua
  [5:2] SYLODIVLDOTRIMNDIO
    0=vreg_1p08; 1=vreg_1p11; 2=vreg_1p15; 3=vreg_1p18; 4=vreg_1p21; 5=vreg_1p24; 6=vreg_1p27; 7=vreg_1p29; 8=vreg_1p32; 9=vreg_1p34
  [1:0] SYLODIVLDOTRIMCORE
    0=RXLO; 3=TXLO
0x158 SYCAL reset 0x1008100
  [25:24] SYHILOADCHPREG
    0=i_350uA; 1=i_500uA; 2=i_550uA; 3=i_700uA
  [16:15] SYVCOVCAPVCM
  [10] SYVCOSLOWNOISEFILTER
    0=slow_noise_filter_0; 1=slow_noise_filter_1
  [9] SYVCOMORECURRENT
    0=more_current_0; 1=more_current_1
  [8] SYVCOMODEPKD
    0=t_openloop_0; 1=t_pkdetect_1
0x15C SYEN
  [14] SYSTARTMMDREG
    0=no_fast_startup; 1=fast_startup
  [13] SYSTARTCHPREG
    0=no_fast_startup; 1=fast_startup
  [12] SYLODIVLDOEN
    0=disable; 1=enable
  [11] SYLODIVLDOBIASEN
    0=disable; 1=enable
  [10] SYLODIVEN
    0=disable; 1=enable
  [9] SYENVCOREG
    0=en_vco_reg_0; 1=en_vco_reg_1
  [8] SYENVCOPFET
    0=en_vco_pfet_0; 1=en_vco_pfet_1
  [7] SYENVCOBIAS
    0=en_vco_bias_0; 1=en_vco_bias_1
  [6] SYENMMDREPLICA2
    0=Disable; 1=Enable
  [5] SYENMMDREPLICA1
    0=disable; 1=enable
  [4] SYENMMDREG
    0=Disable; 1=Enable
  [3] SYENCHPREPLICA
    0=disable; 1=enable
  [2] SYENCHPREG
    0=Disable; 1=Enable
  [1] SYCHPLPEN
    0=disable; 1=enable
  [0] SYCHPEN
    0=disable; 1=enable
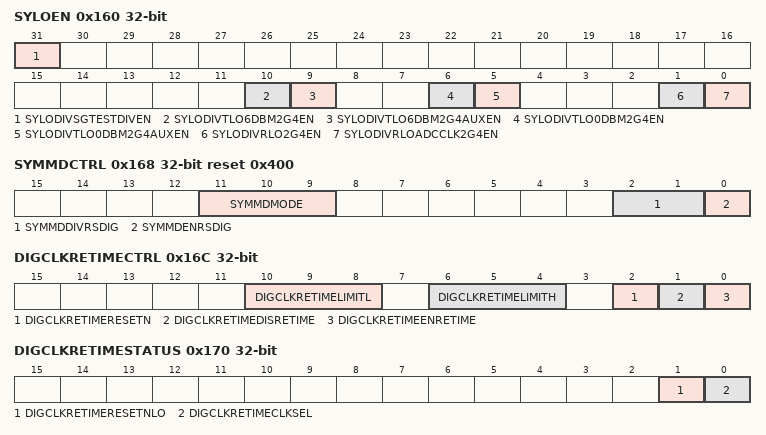
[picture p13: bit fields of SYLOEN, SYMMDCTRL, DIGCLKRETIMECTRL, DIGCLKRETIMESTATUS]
0x160 SYLOEN
  [all] fields
    0=disable; 1=enable
  [31] SYLODIVSGTESTDIVEN
  [10] SYLODIVTLO6DBM2G4EN
  [9] SYLODIVTLO6DBM2G4AUXEN
  [6] SYLODIVTLO0DBM2G4EN
  [5] SYLODIVTLO0DBM2G4AUXEN
  [1] SYLODIVRLO2G4EN
  [0] SYLODIVRLOADCCLK2G4EN
0x168 SYMMDCTRL reset 0x400
  [11:9] SYMMDMODE
    0=rx_w_swctrl; 1=rx_wo_swctrl; 2=qnc_dsm2; 3=qnc_dsm3; 4=rxlp_wo_swctrl; 5=notuse_5; 6=notuse_6; 7=notuse_7
  [2:1] SYMMDDIVRSDIG
    0=Divideby1; 1=Divideby2; 2=Divideby4; 3=Divideby8
  [0] SYMMDENRSDIG
    0=disable; 1=enable
0x16C DIGCLKRETIMECTRL
  [10:8] DIGCLKRETIMELIMITL
  [6:4] DIGCLKRETIMELIMITH
  [2] DIGCLKRETIMERESETN
    0=reset; 1=operate
  [1] DIGCLKRETIMEDISRETIME
    0=enable_retime; 1=disable_retime
  [0] DIGCLKRETIMEENRETIME
    0=disable; 1=enable
0x170 DIGCLKRETIMESTATUS ro
  [1] DIGCLKRETIMERESETNLO
    0=lo; 1=hi
  [0] DIGCLKRETIMECLKSEL
    0=use_raw_clk; 1=use_retimed_clk
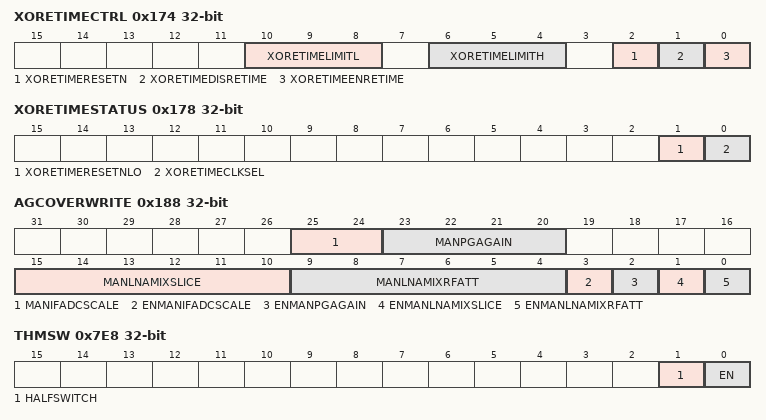
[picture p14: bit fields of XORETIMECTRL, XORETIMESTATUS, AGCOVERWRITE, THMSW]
0x174 XORETIMECTRL
  [10:8] XORETIMELIMITL
  [6:4] XORETIMELIMITH
  [2] XORETIMERESETN
    0=operate; 1=reset
  [1] XORETIMEDISRETIME
    0=enable_retime; 1=disable_retime
  [0] XORETIMEENRETIME
    0=disable; 1=enable
0x178 XORETIMESTATUS ro
  [1] XORETIMERESETNLO
    0=lo; 1=hi
  [0] XORETIMECLKSEL
    0=use_raw_clk; 1=use_retimed_clk
0x17C XOSQBUFFILT
  [1:0] XOSQBUFFILT
    0=bypass; 1=filter_1; 2=filter_2; 3=filter_3
0x188 AGCOVERWRITE
  [25:24] MANIFADCSCALE — RAC Overwite PGA
  [23:20] MANPGAGAIN — RAC Overwite PGA
  [15:10] MANLNAMIXSLICE — RAC Overwite LNA
  [9:4] MANLNAMIXRFATT — RAC Overwite PN
  [3] ENMANIFADCSCALE — Enable RAC Overwite PN
  [2] ENMANPGAGAIN — Enable RAC Overwite PGA
  [1] ENMANLNAMIXSLICE — Enable RAC Overwite LNA
  [0] ENMANLNAMIXRFATT — Enable RAC Overwite PN
{0x3E0+4i} SCRATCH{i} (i=0..7)
0x7E8 THMSW
  [1] HALFSWITCH — Halfswitch Mode enable
    0=Disabled; 1=Enabled
  [0] EN — Enable Switch
    0=Disabled; 1=Enabled
